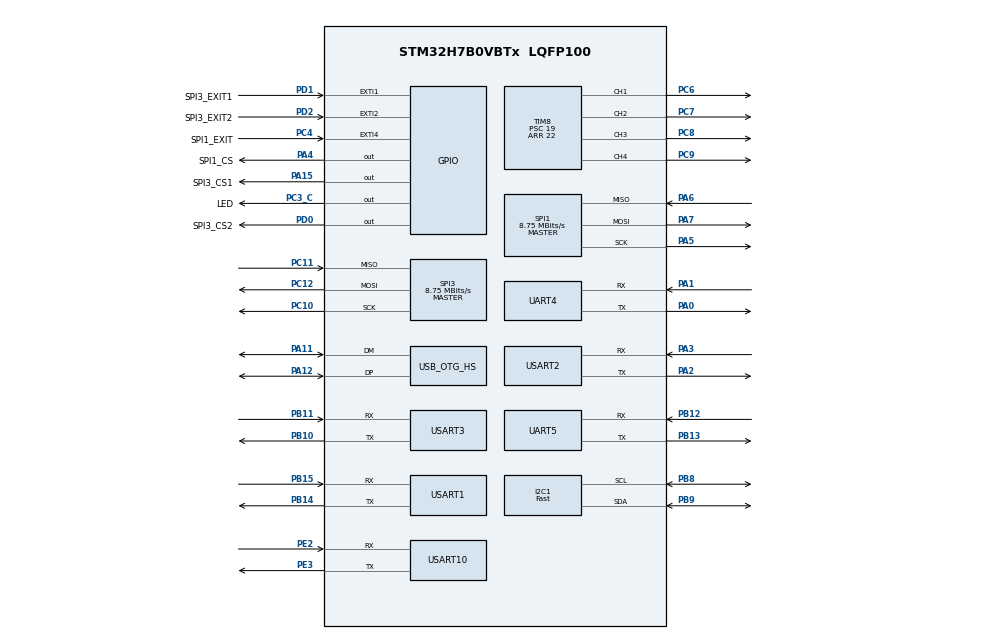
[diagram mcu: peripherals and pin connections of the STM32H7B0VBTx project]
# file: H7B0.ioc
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CORTEX_M7.CPU_DCache=Disabled
CORTEX_M7.CPU_ICache=Disabled
CORTEX_M7.default_mode_Activation=1
Dma.I2C1_RX.6.Direction=DMA_PERIPH_TO_MEMORY
Dma.I2C1_RX.6.EventEnable=DISABLE
Dma.I2C1_RX.6.FIFOMode=DMA_FIFOMODE_DISABLE
Dma.I2C1_RX.6.Instance=DMA1_Stream6
Dma.I2C1_RX.6.MemDataAlignment=DMA_MDATAALIGN_BYTE
Dma.I2C1_RX.6.MemInc=DMA_MINC_ENABLE
Dma.I2C1_RX.6.Mode=DMA_NORMAL
Dma.I2C1_RX.6.PeriphDataAlignment=DMA_PDATAALIGN_BYTE
Dma.I2C1_RX.6.PeriphInc=DMA_PINC_DISABLE
Dma.I2C1_RX.6.Polarity=HAL_DMAMUX_REQ_GEN_RISING
Dma.I2C1_RX.6.Priority=DMA_PRIORITY_LOW
Dma.I2C1_RX.6.RequestNumber=1
Dma.I2C1_RX.6.SignalID=NONE
Dma.I2C1_RX.6.SyncEnable=DISABLE
Dma.I2C1_RX.6.SyncPolarity=HAL_DMAMUX_SYNC_NO_EVENT
Dma.I2C1_RX.6.SyncRequestNumber=1
Dma.I2C1_RX.6.SyncSignalID=NONE
Dma.I2C1_TX.7.Direction=DMA_MEMORY_TO_PERIPH
Dma.I2C1_TX.7.EventEnable=DISABLE
Dma.I2C1_TX.7.FIFOMode=DMA_FIFOMODE_DISABLE
Dma.I2C1_TX.7.Instance=DMA1_Stream7
Dma.I2C1_TX.7.MemDataAlignment=DMA_MDATAALIGN_BYTE
Dma.I2C1_TX.7.MemInc=DMA_MINC_ENABLE
Dma.I2C1_TX.7.Mode=DMA_NORMAL
Dma.I2C1_TX.7.PeriphDataAlignment=DMA_PDATAALIGN_BYTE
Dma.I2C1_TX.7.PeriphInc=DMA_PINC_DISABLE
Dma.I2C1_TX.7.Polarity=HAL_DMAMUX_REQ_GEN_RISING
Dma.I2C1_TX.7.Priority=DMA_PRIORITY_LOW
Dma.I2C1_TX.7.RequestNumber=1
Dma.I2C1_TX.7.SignalID=NONE
Dma.I2C1_TX.7.SyncEnable=DISABLE
Dma.I2C1_TX.7.SyncPolarity=HAL_DMAMUX_SYNC_NO_EVENT
Dma.I2C1_TX.7.SyncRequestNumber=1
Dma.I2C1_TX.7.SyncSignalID=NONE
Dma.Request0=TIM8_CH1
Dma.Request1=TIM8_CH2
Dma.Request2=TIM8_CH3
Dma.Request3=TIM8_CH4
Dma.Request4=USART1_RX
Dma.Request5=USART1_TX
Dma.Request6=I2C1_RX
Dma.Request7=I2C1_TX
Dma.TIM8_CH1.0.Direction=DMA_MEMORY_TO_PERIPH
Dma.TIM8_CH1.0.EventEnable=DISABLE
Dma.TIM8_CH1.0.FIFOMode=DMA_FIFOMODE_DISABLE
Dma.TIM8_CH1.0.Instance=DMA1_Stream0
Dma.TIM8_CH1.0.MemDataAlignment=DMA_MDATAALIGN_HALFWORD
Dma.TIM8_CH1.0.MemInc=DMA_MINC_ENABLE
Dma.TIM8_CH1.0.Mode=DMA_NORMAL
Dma.TIM8_CH1.0.PeriphDataAlignment=DMA_PDATAALIGN_HALFWORD
Dma.TIM8_CH1.0.PeriphInc=DMA_PINC_DISABLE
Dma.TIM8_CH1.0.Polarity=HAL_DMAMUX_REQ_GEN_RISING
Dma.TIM8_CH1.0.Priority=DMA_PRIORITY_HIGH
Dma.TIM8_CH1.0.RequestNumber=1
Dma.TIM8_CH1.0.SignalID=NONE
Dma.TIM8_CH1.0.SyncEnable=DISABLE
Dma.TIM8_CH1.0.SyncPolarity=HAL_DMAMUX_SYNC_NO_EVENT
Dma.TIM8_CH1.0.SyncRequestNumber=1
Dma.TIM8_CH1.0.SyncSignalID=NONE
Dma.TIM8_CH2.1.Direction=DMA_MEMORY_TO_PERIPH
Dma.TIM8_CH2.1.EventEnable=DISABLE
Dma.TIM8_CH2.1.FIFOMode=DMA_FIFOMODE_DISABLE
Dma.TIM8_CH2.1.Instance=DMA1_Stream1
Dma.TIM8_CH2.1.MemDataAlignment=DMA_MDATAALIGN_HALFWORD
Dma.TIM8_CH2.1.MemInc=DMA_MINC_ENABLE
Dma.TIM8_CH2.1.Mode=DMA_NORMAL
Dma.TIM8_CH2.1.PeriphDataAlignment=DMA_PDATAALIGN_HALFWORD
Dma.TIM8_CH2.1.PeriphInc=DMA_PINC_DISABLE
Dma.TIM8_CH2.1.Polarity=HAL_DMAMUX_REQ_GEN_RISING
Dma.TIM8_CH2.1.Priority=DMA_PRIORITY_HIGH
Dma.TIM8_CH2.1.RequestNumber=1
Dma.TIM8_CH2.1.SignalID=NONE
Dma.TIM8_CH2.1.SyncEnable=DISABLE
Dma.TIM8_CH2.1.SyncPolarity=HAL_DMAMUX_SYNC_NO_EVENT
Dma.TIM8_CH2.1.SyncRequestNumber=1
Dma.TIM8_CH2.1.SyncSignalID=NONE
Dma.TIM8_CH3.2.Direction=DMA_MEMORY_TO_PERIPH
Dma.TIM8_CH3.2.EventEnable=DISABLE
Dma.TIM8_CH3.2.FIFOMode=DMA_FIFOMODE_DISABLE
Dma.TIM8_CH3.2.Instance=DMA1_Stream2
Dma.TIM8_CH3.2.MemDataAlignment=DMA_MDATAALIGN_HALFWORD
Dma.TIM8_CH3.2.MemInc=DMA_MINC_ENABLE
Dma.TIM8_CH3.2.Mode=DMA_NORMAL
Dma.TIM8_CH3.2.PeriphDataAlignment=DMA_PDATAALIGN_HALFWORD
Dma.TIM8_CH3.2.PeriphInc=DMA_PINC_DISABLE
Dma.TIM8_CH3.2.Polarity=HAL_DMAMUX_REQ_GEN_RISING
Dma.TIM8_CH3.2.Priority=DMA_PRIORITY_HIGH
Dma.TIM8_CH3.2.RequestNumber=1
Dma.TIM8_CH3.2.SignalID=NONE
Dma.TIM8_CH3.2.SyncEnable=DISABLE
Dma.TIM8_CH3.2.SyncPolarity=HAL_DMAMUX_SYNC_NO_EVENT
Dma.TIM8_CH3.2.SyncRequestNumber=1
Dma.TIM8_CH3.2.SyncSignalID=NONE
Dma.TIM8_CH4.3.Direction=DMA_MEMORY_TO_PERIPH
Dma.TIM8_CH4.3.EventEnable=DISABLE
Dma.TIM8_CH4.3.FIFOMode=DMA_FIFOMODE_DISABLE
Dma.TIM8_CH4.3.Instance=DMA1_Stream3
Dma.TIM8_CH4.3.MemDataAlignment=DMA_MDATAALIGN_HALFWORD
Dma.TIM8_CH4.3.MemInc=DMA_MINC_ENABLE
Dma.TIM8_CH4.3.Mode=DMA_NORMAL
Dma.TIM8_CH4.3.PeriphDataAlignment=DMA_PDATAALIGN_HALFWORD
Dma.TIM8_CH4.3.PeriphInc=DMA_PINC_DISABLE
Dma.TIM8_CH4.3.Polarity=HAL_DMAMUX_REQ_GEN_RISING
Dma.TIM8_CH4.3.Priority=DMA_PRIORITY_HIGH
Dma.TIM8_CH4.3.RequestNumber=1
Dma.TIM8_CH4.3.SignalID=NONE
Dma.TIM8_CH4.3.SyncEnable=DISABLE
Dma.TIM8_CH4.3.SyncPolarity=HAL_DMAMUX_SYNC_NO_EVENT
Dma.TIM8_CH4.3.SyncRequestNumber=1
Dma.TIM8_CH4.3.SyncSignalID=NONE
Dma.USART1_RX.4.Direction=DMA_PERIPH_TO_MEMORY
Dma.USART1_RX.4.EventEnable=DISABLE
Dma.USART1_RX.4.FIFOMode=DMA_FIFOMODE_DISABLE
Dma.USART1_RX.4.Instance=DMA1_Stream4
Dma.USART1_RX.4.MemDataAlignment=DMA_MDATAALIGN_BYTE
Dma.USART1_RX.4.MemInc=DMA_MINC_ENABLE
Dma.USART1_RX.4.Mode=DMA_NORMAL
Dma.USART1_RX.4.PeriphDataAlignment=DMA_PDATAALIGN_BYTE
Dma.USART1_RX.4.PeriphInc=DMA_PINC_DISABLE
Dma.USART1_RX.4.Polarity=HAL_DMAMUX_REQ_GEN_RISING
Dma.USART1_RX.4.Priority=DMA_PRIORITY_LOW
Dma.USART1_RX.4.RequestNumber=1
Dma.USART1_RX.4.SignalID=NONE
Dma.USART1_RX.4.SyncEnable=DISABLE
Dma.USART1_RX.4.SyncPolarity=HAL_DMAMUX_SYNC_NO_EVENT
Dma.USART1_RX.4.SyncRequestNumber=1
Dma.USART1_RX.4.SyncSignalID=NONE
Dma.USART1_TX.5.Direction=DMA_MEMORY_TO_PERIPH
Dma.USART1_TX.5.EventEnable=DISABLE
Dma.USART1_TX.5.FIFOMode=DMA_FIFOMODE_DISABLE
Dma.USART1_TX.5.Instance=DMA1_Stream5
Dma.USART1_TX.5.MemDataAlignment=DMA_MDATAALIGN_BYTE
Dma.USART1_TX.5.MemInc=DMA_MINC_ENABLE
Dma.USART1_TX.5.Mode=DMA_NORMAL
Dma.USART1_TX.5.PeriphDataAlignment=DMA_PDATAALIGN_BYTE
Dma.USART1_TX.5.PeriphInc=DMA_PINC_DISABLE
Dma.USART1_TX.5.Polarity=HAL_DMAMUX_REQ_GEN_RISING
Dma.USART1_TX.5.Priority=DMA_PRIORITY_LOW
Dma.USART1_TX.5.RequestNumber=1
Dma.USART1_TX.5.SignalID=NONE
Dma.USART1_TX.5.SyncEnable=DISABLE
Dma.USART1_TX.5.SyncPolarity=HAL_DMAMUX_SYNC_NO_EVENT
Dma.USART1_TX.5.SyncRequestNumber=1
Dma.USART1_TX.5.SyncSignalID=NONE
FREERTOS.INCLUDE_vTaskDelayUntil=1
FREERTOS.Tasks01=defaultTask,8,128,StartDefaultTask,As weak,NULL,Dynamic,NULL,NULL
FREERTOS.configENABLE_FPU=1
FREERTOS.configTOTAL_HEAP_SIZE=131072
I2C1.CustomTiming=Enabled
I2C1.I2C_Speed_Mode=I2C_Fast
I2C1.Timing=0x00D04BFF
Mcu.Family=STM32H7
Mcu.Name=STM32H7B0VBTx
Mcu.Package=LQFP100
NVIC.DMA1_Stream0_IRQn=true\:5\:0\:false\:false\:true\:true\:false\:true\:true
NVIC.DMA1_Stream1_IRQn=true\:5\:0\:false\:false\:true\:true\:false\:true\:true
NVIC.DMA1_Stream2_IRQn=true\:5\:0\:false\:false\:true\:true\:false\:true\:true
NVIC.DMA1_Stream3_IRQn=true\:5\:0\:false\:false\:true\:true\:false\:true\:true
NVIC.DMA1_Stream4_IRQn=true\:5\:0\:false\:false\:true\:true\:false\:true\:true
NVIC.DMA1_Stream5_IRQn=true\:5\:0\:false\:false\:true\:true\:false\:true\:true
NVIC.DMA1_Stream6_IRQn=true\:5\:0\:false\:false\:true\:true\:false\:true\:true
NVIC.DMA1_Stream7_IRQn=true\:5\:0\:false\:false\:true\:true\:false\:true\:true
NVIC.EXTI1_IRQn=true\:5\:0\:false\:false\:true\:true\:true\:true\:true
NVIC.EXTI2_IRQn=true\:5\:0\:true\:false\:true\:true\:true\:true\:true
NVIC.EXTI4_IRQn=true\:5\:0\:true\:false\:true\:true\:true\:true\:true
NVIC.I2C1_EV_IRQn=true\:5\:0\:false\:false\:true\:true\:true\:true\:true
NVIC.OTG_HS_IRQn=true\:5\:0\:false\:false\:true\:true\:false\:true\:true
NVIC.PriorityGroup=NVIC_PRIORITYGROUP_4
NVIC.TIM1_UP_IRQn=true\:15\:0\:false\:false\:true\:false\:false\:true\:true
NVIC.TimeBase=TIM1_UP_IRQn
NVIC.TimeBaseIP=TIM1
NVIC.USART1_IRQn=true\:5\:0\:false\:false\:true\:true\:true\:true\:true
PA0.Mode=Asynchronous
PA0.Signal=UART4_TX
PA1.Mode=Asynchronous
PA1.Signal=UART4_RX
PA11.GPIO_Speed=GPIO_SPEED_FREQ_VERY_HIGH
PA11.Mode=Device_Only_FS
PA11.Signal=USB_OTG_HS_DM
PA12.GPIO_Speed=GPIO_SPEED_FREQ_VERY_HIGH
PA12.Mode=Device_Only_FS
PA12.Signal=USB_OTG_HS_DP
PA13.Mode=Serial_Wire
PA13.Signal=DEBUG_JTMS-SWDIO
PA14.Mode=Serial_Wire
PA14.Signal=DEBUG_JTCK-SWCLK
PA15.GPIO_Label=SPI3_CS1
PA15.GPIO_Speed=GPIO_SPEED_FREQ_HIGH
PA15.PinState=GPIO_PIN_SET
PA15.Signal=GPIO_Output
PA2.Mode=Asynchronous
PA2.Signal=USART2_TX
PA3.Mode=Asynchronous
PA3.Signal=USART2_RX
PA4.GPIO_Label=SPI1_CS
PA4.GPIO_Speed=GPIO_SPEED_FREQ_HIGH
PA4.PinState=GPIO_PIN_SET
PA4.Signal=GPIO_Output
PA5.GPIO_PuPd=GPIO_PULLUP
PA5.GPIO_Speed=GPIO_SPEED_FREQ_VERY_HIGH
PA5.Mode=Full_Duplex_Master
PA5.Signal=SPI1_SCK
PA6.GPIO_Speed=GPIO_SPEED_FREQ_VERY_HIGH
PA6.Mode=Full_Duplex_Master
PA6.Signal=SPI1_MISO
PA7.GPIO_Speed=GPIO_SPEED_FREQ_VERY_HIGH
PA7.Mode=Full_Duplex_Master
PA7.Signal=SPI1_MOSI
PB10.Mode=Asynchronous
PB10.Signal=USART3_TX
PB11.Mode=Asynchronous
PB11.Signal=USART3_RX
PB12.Mode=Asynchronous
PB12.Signal=UART5_RX
PB13.Mode=Asynchronous
PB13.Signal=UART5_TX
PB14.Mode=Asynchronous
PB14.Signal=USART1_TX
PB15.Mode=Asynchronous
PB15.Signal=USART1_RX
PB8.GPIO_Speed=GPIO_SPEED_FREQ_HIGH
PB8.Mode=I2C
PB8.Signal=I2C1_SCL
PB9.GPIO_Speed=GPIO_SPEED_FREQ_HIGH
PB9.Mode=I2C
PB9.Signal=I2C1_SDA
PC10.GPIO_PuPd=GPIO_PULLUP
PC10.GPIO_Speed=GPIO_SPEED_FREQ_VERY_HIGH
PC10.Mode=Full_Duplex_Master
PC10.Signal=SPI3_SCK
PC11.GPIO_Speed=GPIO_SPEED_FREQ_VERY_HIGH
PC11.Mode=Full_Duplex_Master
PC11.Signal=SPI3_MISO
PC12.GPIO_Speed=GPIO_SPEED_FREQ_VERY_HIGH
PC12.Mode=Full_Duplex_Master
PC12.Signal=SPI3_MOSI
PC3_C.GPIO_Label=LED
PC3_C.Signal=GPIO_Output
PC4.GPIO_Label=SPI1_EXIT
PC4.Signal=GPXTI4
PC6.GPIO_PuPd=GPIO_PULLDOWN
PC6.GPIO_Speed=GPIO_SPEED_FREQ_VERY_HIGH
PC6.Signal=S_TIM8_CH1
PC7.GPIO_PuPd=GPIO_PULLDOWN
PC7.GPIO_Speed=GPIO_SPEED_FREQ_VERY_HIGH
PC7.Signal=S_TIM8_CH2
PC8.GPIO_PuPd=GPIO_PULLDOWN
PC8.GPIO_Speed=GPIO_SPEED_FREQ_VERY_HIGH
PC8.Signal=S_TIM8_CH3
PC9.GPIO_PuPd=GPIO_PULLDOWN
PC9.GPIO_Speed=GPIO_SPEED_FREQ_VERY_HIGH
PC9.Signal=S_TIM8_CH4
PD0.GPIO_Label=SPI3_CS2
PD0.GPIO_Speed=GPIO_SPEED_FREQ_HIGH
PD0.PinState=GPIO_PIN_SET
PD0.Signal=GPIO_Output
PD1.GPIO_Label=SPI3_EXIT1
PD1.Signal=GPXTI1
PD2.GPIO_Label=SPI3_EXIT2
PD2.Signal=GPXTI2
PE2.Mode=Asynchronous
PE2.Signal=USART10_RX
PE3.Mode=Asynchronous
PE3.Signal=USART10_TX
PH0-OSC_IN.Mode=HSE-External-Oscillator
PH0-OSC_IN.Signal=RCC_OSC_IN
PH1-OSC_OUT.Mode=HSE-External-Oscillator
PH1-OSC_OUT.Signal=RCC_OSC_OUT
ProjectManager.HeapSize=0x2000
ProjectManager.StackSize=0x1000
ProjectManager.TargetToolchain=Makefile
RCC.ADCFreq_Value=250000000
RCC.APB1Freq_Value=140000000
RCC.APB2Freq_Value=140000000
RCC.APB3Freq_Value=140000000
RCC.APB4Freq_Value=140000000
RCC.CDPPRE=RCC_APB3_DIV2
RCC.CDPPRE1=RCC_APB1_DIV2
RCC.CDPPRE2=RCC_APB2_DIV2
RCC.CortexFreq_Value=280000000
RCC.DIVM1=5
RCC.DIVM2=5
RCC.DIVN1=112
RCC.DIVN2=100
RCC.HCLKFreq_Value=280000000
RCC.HSE_VALUE=25000000
RCC.PLL2_VCI_Range-AdvancedSettings=RCC_PLL2VCIRANGE_3
RCC.PLLSourceVirtual=RCC_PLLSOURCE_HSE
RCC.SRDPPRE=RCC_APB4_DIV2
RCC.SYSCLKFreq_VALUE=280000000
RCC.SYSCLKSource=RCC_SYSCLKSOURCE_PLLCLK
RCC.USBCLockSelection=RCC_USBCLKSOURCE_HSI48
RCC.USBFreq_Value=48000000
SH.S_TIM8_CH1.0=TIM8_CH1,PWM Generation1 CH1
SH.S_TIM8_CH2.0=TIM8_CH2,PWM Generation2 CH2
SH.S_TIM8_CH3.0=TIM8_CH3,PWM Generation3 CH3
SH.S_TIM8_CH4.0=TIM8_CH4,PWM Generation4 CH4
SPI1.BaudRatePrescaler=SPI_BAUDRATEPRESCALER_32
SPI1.CLKPhase=SPI_PHASE_2EDGE
SPI1.CLKPolarity=SPI_POLARITY_HIGH
SPI1.CalculateBaudRate=8.75 MBits/s
SPI1.DataSize=SPI_DATASIZE_8BIT
SPI1.Direction=SPI_DIRECTION_2LINES
SPI1.MasterKeepIOState=SPI_MASTER_KEEP_IO_STATE_ENABLE
SPI1.Mode=SPI_MODE_MASTER
SPI1.VirtualType=VM_MASTER
SPI3.BaudRatePrescaler=SPI_BAUDRATEPRESCALER_32
SPI3.CLKPhase=SPI_PHASE_2EDGE
SPI3.CLKPolarity=SPI_POLARITY_HIGH
SPI3.CalculateBaudRate=8.75 MBits/s
SPI3.DataSize=SPI_DATASIZE_8BIT
SPI3.Direction=SPI_DIRECTION_2LINES
SPI3.MasterKeepIOState=SPI_MASTER_KEEP_IO_STATE_ENABLE
SPI3.Mode=SPI_MODE_MASTER
SPI3.VirtualType=VM_MASTER
TIM8.Channel-PWM\ Generation1\ CH1=TIM_CHANNEL_1
TIM8.Channel-PWM\ Generation2\ CH2=TIM_CHANNEL_2
TIM8.Channel-PWM\ Generation3\ CH3=TIM_CHANNEL_3
TIM8.Channel-PWM\ Generation4\ CH4=TIM_CHANNEL_4
TIM8.Period=22
TIM8.Prescaler=19
USART1.VirtualMode-Asynchronous=VM_ASYNC
USART10.VirtualMode=VM_ASYNC
USART2.VirtualMode-Asynchronous=VM_ASYNC
USART3.VirtualMode-Asynchronous=VM_ASYNC
USB_DEVICE.CLASS_NAME_HS=CDC
USB_DEVICE.VirtualMode-CDC_HS=Cdc
USB_DEVICE.VirtualModeHS=Cdc_HS
USB_OTG_HS.VirtualMode-Device_Only_FS=Device_Only_FS
VP_FREERTOS_VS_CMSIS_V2.Mode=CMSIS_V2
VP_SYS_VS_tim1.Mode=TIM1
VP_TIM8_VS_ClockSourceINT.Mode=Internal
VP_USB_DEVICE_VS_USB_DEVICE_CDC_HS.Mode=CDC_HS
board=custom

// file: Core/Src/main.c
/* USER CODE BEGIN Header */
/**
 ******************************************************************************
 * @file           : main.c
 * @brief          : Main program body
 ******************************************************************************
 * @attention
 *
 * Copyright (c) 2022 STMicroelectronics.
 * All rights reserved.
 *
 * This software is licensed under terms that can be found in the LICENSE file
 * in the root directory of this software component.
 * If no LICENSE file comes with this software, it is provided AS-IS.
 *
 ******************************************************************************
 */
/* USER CODE END Header */
#include "main.h"
#include "cmsis_os.h"
#include "dma.h"
#include "i2c.h"
#include "spi.h"
#include "tim.h"
#include "usart.h"
#include "usb_device.h"
#include "gpio.h"

void SystemClock_Config(void);
static void MPU_Config(void);
void MX_FREERTOS_Init(void);

int main(void)
{

  /* MPU Configuration--------------------------------------------------------*/
  MPU_Config();

  /* MCU Configuration--------------------------------------------------------*/

  /* Reset of all peripherals, Initializes the Flash interface and the Systick. */
  HAL_Init();

  /* Configure the system clock */
  SystemClock_Config();

  /* Initialize all configured peripherals */
  MX_GPIO_Init();
  MX_DMA_Init();
  MX_I2C1_Init();
  MX_SPI1_Init();
  MX_TIM8_Init();
  MX_UART4_Init();
  MX_UART5_Init();
  MX_USART1_UART_Init();
  MX_USART2_UART_Init();
  MX_USART3_UART_Init();
  MX_USART10_UART_Init();
  MX_SPI3_Init();
  /* USER CODE BEGIN 2 */
  MX_USB_DEVICE_Init();
  /* USER CODE END 2 */

  /* Init scheduler */
  osKernelInitialize();  /* Call init function for freertos objects (in freertos.c) */
  MX_FREERTOS_Init();

  /* Start scheduler */
  osKernelStart();

  /* We should never get here as control is now taken by the scheduler */
  /* Infinite loop */
  while (1)
  {

  }
}

void SystemClock_Config(void)
{
  RCC_OscInitTypeDef RCC_OscInitStruct = {0};
  RCC_ClkInitTypeDef RCC_ClkInitStruct = {0};

  /*AXI clock gating */
  RCC->CKGAENR = 0xFFFFFFFF;

  /** Supply configuration update enable
  */
  HAL_PWREx_ConfigSupply(PWR_LDO_SUPPLY);

  /** Configure the main internal regulator output voltage
  */
  __HAL_PWR_VOLTAGESCALING_CONFIG(PWR_REGULATOR_VOLTAGE_SCALE0);

  while(!__HAL_PWR_GET_FLAG(PWR_FLAG_VOSRDY)) {}

  /** Initializes the RCC Oscillators according to the specified parameters
  * in the RCC_OscInitTypeDef structure.
  */
  RCC_OscInitStruct.OscillatorType = RCC_OSCILLATORTYPE_HSI48|RCC_OSCILLATORTYPE_HSE;
  RCC_OscInitStruct.HSEState = RCC_HSE_ON;
  RCC_OscInitStruct.HSI48State = RCC_HSI48_ON;
  RCC_OscInitStruct.PLL.PLLState = RCC_PLL_ON;
  RCC_OscInitStruct.PLL.PLLSource = RCC_PLLSOURCE_HSE;
  RCC_OscInitStruct.PLL.PLLM = 5;
  RCC_OscInitStruct.PLL.PLLN = 112;
  RCC_OscInitStruct.PLL.PLLP = 2;
  RCC_OscInitStruct.PLL.PLLQ = 2;
  RCC_OscInitStruct.PLL.PLLR = 2;
  RCC_OscInitStruct.PLL.PLLRGE = RCC_PLL1VCIRANGE_2;
  RCC_OscInitStruct.PLL.PLLVCOSEL = RCC_PLL1VCOWIDE;
  RCC_OscInitStruct.PLL.PLLFRACN = 0;
  if (HAL_RCC_OscConfig(&RCC_OscInitStruct) != HAL_OK)
  {
    Error_Handler();
  }

  /** Initializes the CPU, AHB and APB buses clocks
  */
  RCC_ClkInitStruct.ClockType = RCC_CLOCKTYPE_HCLK|RCC_CLOCKTYPE_SYSCLK
                              |RCC_CLOCKTYPE_PCLK1|RCC_CLOCKTYPE_PCLK2
                              |RCC_CLOCKTYPE_D3PCLK1|RCC_CLOCKTYPE_D1PCLK1;
  RCC_ClkInitStruct.SYSCLKSource = RCC_SYSCLKSOURCE_PLLCLK;
  RCC_ClkInitStruct.SYSCLKDivider = RCC_SYSCLK_DIV1;
  RCC_ClkInitStruct.AHBCLKDivider = RCC_HCLK_DIV1;
  RCC_ClkInitStruct.APB3CLKDivider = RCC_APB3_DIV2;
  RCC_ClkInitStruct.APB1CLKDivider = RCC_APB1_DIV2;
  RCC_ClkInitStruct.APB2CLKDivider = RCC_APB2_DIV2;
  RCC_ClkInitStruct.APB4CLKDivider = RCC_APB4_DIV2;

  if (HAL_RCC_ClockConfig(&RCC_ClkInitStruct, FLASH_LATENCY_7) != HAL_OK)
  {
    Error_Handler();
  }
}

/* MPU Configuration */

void MPU_Config(void)
{
  MPU_Region_InitTypeDef MPU_InitStruct = {0};

  /* Disables the MPU */
  HAL_MPU_Disable();

  /** Initializes and configures the Region and the memory to be protected
  */
  MPU_InitStruct.Enable = MPU_REGION_ENABLE;
  MPU_InitStruct.Number = MPU_REGION_NUMBER0;
  MPU_InitStruct.BaseAddress = 0x0;
  MPU_InitStruct.Size = MPU_REGION_SIZE_4GB;
  MPU_InitStruct.SubRegionDisable = 0x87;
  MPU_InitStruct.TypeExtField = MPU_TEX_LEVEL0;
  MPU_InitStruct.AccessPermission = MPU_REGION_NO_ACCESS;
  MPU_InitStruct.DisableExec = MPU_INSTRUCTION_ACCESS_DISABLE;
  MPU_InitStruct.IsShareable = MPU_ACCESS_SHAREABLE;
  MPU_InitStruct.IsCacheable = MPU_ACCESS_NOT_CACHEABLE;
  MPU_InitStruct.IsBufferable = MPU_ACCESS_NOT_BUFFERABLE;

  HAL_MPU_ConfigRegion(&MPU_InitStruct);
  /* Enables the MPU */
  HAL_MPU_Enable(MPU_PRIVILEGED_DEFAULT);

}

void HAL_TIM_PeriodElapsedCallback(TIM_HandleTypeDef *htim)
{
  if (htim->Instance == TIM1) {
    HAL_IncTick();
  }
}

void Error_Handler(void)
{
  __disable_irq();
  while (1)
  {
  }
}

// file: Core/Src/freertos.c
/* USER CODE BEGIN Header */
/**
  ******************************************************************************
  * File Name          : freertos.c
  * Description        : Code for freertos applications
  ******************************************************************************
  * @attention
  *
  * Copyright (c) 2022 STMicroelectronics.
  * All rights reserved.
  *
  * This software is licensed under terms that can be found in the LICENSE file
  * in the root directory of this software component.
  * If no LICENSE file comes with this software, it is provided AS-IS.
  *
  ******************************************************************************
  */
/* USER CODE END Header */

#include "FreeRTOS.h"
#include "task.h"
#include "main.h"
#include "cmsis_os.h"

/* USER CODE BEGIN Includes */
#include "flight_task.h"
/* USER CODE END Includes */

/* Definitions for defaultTask */
osThreadId_t defaultTaskHandle;
const osThreadAttr_t defaultTask_attributes = {
  .name = "defaultTask",
  .stack_size = 128 * 4,
  .priority = (osPriority_t) osPriorityLow,
};

void StartDefaultTask(void *argument);

extern void MX_USB_DEVICE_Init(void);
void MX_FREERTOS_Init(void); /* (MISRA C 2004 rule 8.1) */

void MX_FREERTOS_Init(void) {

  /* Create the thread(s) */
  /* creation of defaultTask */
  defaultTaskHandle = osThreadNew(StartDefaultTask, NULL, &defaultTask_attributes);

}

__weak void StartDefaultTask(void *argument)
{
  /* init code for USB_DEVICE */
  MX_USB_DEVICE_Init();
  for(;;)
  {
    osDelay(1);
  }
}
